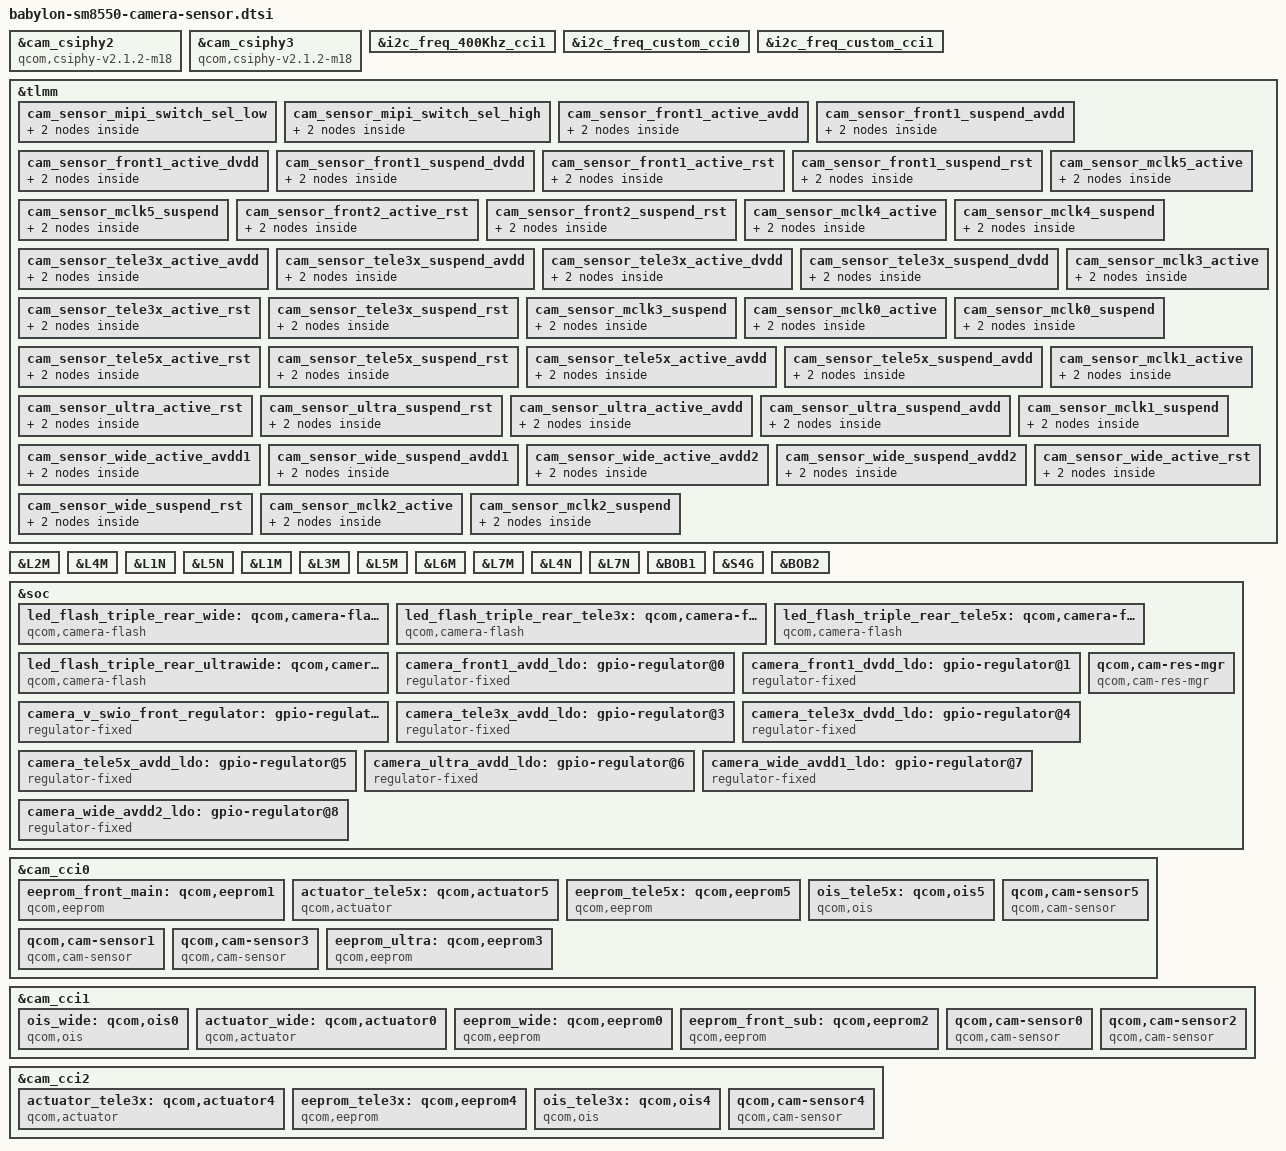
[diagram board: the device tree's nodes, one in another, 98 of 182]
#include <dt-bindings/msm-camera.h>
#include <dt-bindings/gpio/gpio.h>

//wide imx800
&cam_csiphy2 {
	compatible = "qcom,csiphy-v2.1.2-m18", "qcom,csiphy";
};

//tele 5x s5k3k1
&cam_csiphy3 {
	compatible = "qcom,csiphy-v2.1.2-m18", "qcom,csiphy";
};


&i2c_freq_400Khz_cci1 {
	hw-thigh = <38>;
	hw-tlow = <56>;
	hw-tsu-sto = <40>;
	hw-tsu-sta = <40>;
	hw-thd-dat = <22>;
	hw-thd-sta = <35>;
	hw-tbuf = <62>;
	hw-scl-stretch-en = <1>;
	hw-trdhld = <6>;
	hw-tsp = <3>;
	cci-clk-src = <37500000>;
	status = "ok";
};

&i2c_freq_custom_cci0 {
	hw-thigh = <16>;
	hw-tlow = <22>;
	hw-tsu-sto = <17>;
	hw-tsu-sta = <18>;
	hw-thd-dat = <16>;
	hw-thd-sta = <15>;
	hw-tbuf = <24>;
	hw-scl-stretch-en = <1>;
	hw-trdhld = <3>;
	hw-tsp = <3>;
	cci-clk-src = <37500000>;
	status = "ok";
};

&i2c_freq_custom_cci1 {
	hw-thigh = <16>;
	hw-tlow = <22>;
	hw-tsu-sto = <17>;
	hw-tsu-sta = <18>;
	hw-thd-dat = <16>;
	hw-thd-sta = <15>;
	hw-tbuf = <24>;
	hw-scl-stretch-en = <1>;
	hw-trdhld = <3>;
	hw-tsp = <3>;
	cci-clk-src = <37500000>;
	status = "ok";
};

&tlmm {
	cam_sensor_mipi_switch_sel_low: cam_sensor_mipi_switch_sel_low {
		/* MIPI SEL LOW: FRONT(AON) SUB ACTIVE */
		mux {
			pins = "gpio91";
			function = "gpio";
		};

		config {
			pins = "gpio91";
			bias-disable; /* No PULL */
			drive-strength = <2>; /* 2 MA */
		};
	};

	cam_sensor_mipi_switch_sel_high: cam_sensor_mipi_switch_sel_high {
		/* MIPI SEL HIGH: FRONT MAIN ACTIVE */
		mux {
			pins = "gpio91";
			function = "gpio";
		};

		config {
			pins = "gpio91";
			bias-pull-down; /* PULL DOWN */
			drive-strength = <2>; /* 2 MA */
			output-low;
		};
	};
	/* Front1 */
	cam_sensor_front1_active_avdd: cam_sensor_front1_active_avdd {
		mux {
			pins = "gpio180";
			function = "gpio";
		};

		config {
			pins = "gpio180";
			bias-disable; /* No PULL */
			drive-strength = <2>; /* 2 MA */
		};
	};

	cam_sensor_front1_suspend_avdd: cam_sensor_front1_suspend_avdd {
		mux {
			pins = "gpio180";
			function = "gpio";
		};

		config {
			pins = "gpio180";
			bias-pull-down; /* PULL DOWN */
			drive-strength = <2>; /* 2 MA */
			output-low;
		};
	};

	cam_sensor_front1_active_dvdd: cam_sensor_front1_active_dvdd {
		mux {
			pins = "gpio97";
			function = "gpio";
		};

		config {
			pins = "gpio97";
			bias-disable; /* No PULL */
			drive-strength = <2>; /* 2 MA */
		};
	};

	cam_sensor_front1_suspend_dvdd: cam_sensor_front1_suspend_dvdd {
		mux {
			pins = "gpio97";
			function = "gpio";
		};

		config {
			pins = "gpio97";
			bias-pull-down; /* PULL DOWN */
			drive-strength = <2>; /* 2 MA */
			output-low;
		};
	};

	cam_sensor_front1_active_rst: cam_sensor_front1_active_rst {
		mux {
			pins = "gpio42";
			function = "gpio";
		};

		config {
			pins = "gpio42";
			bias-disable; /* No PULL */
			drive-strength = <2>; /* 2 MA */
			qcom,apps;
		};
	};

	cam_sensor_front1_suspend_rst: cam_sensor_front1_suspend_rst {
		mux {
			pins = "gpio42";
			function = "gpio";
		};

		config {
			pins = "gpio42";
			bias-pull-down; /* PULL DOWN */
			drive-strength = <2>; /* 2 MA */
			output-low;
			qcom,remote;
		};
	};

	cam_sensor_mclk5_active: cam_sensor_mclk5_active {
		/* MCLK5 */
		mux {
			pins = "gpio105";
			function = "cam_mclk";
		};

		config {
			pins = "gpio105";
			bias-disable; /* No PULL */
			drive-strength = <4>; /* 4 MA */
		};
	};

	cam_sensor_mclk5_suspend: cam_sensor_mclk5_suspend {
		/* MCLK5 */
		mux {
			pins = "gpio105";
			function = "cam_mclk";
		};

		config {
			pins = "gpio105";
			bias-pull-down; /* PULL DOWN */
			drive-strength = <4>; /* 4 MA */
		};
	};
	/* Front2 */
	cam_sensor_front2_active_rst: cam_sensor_front2_active_rst {
		mux {
			pins = "gpio120";
			function = "gpio";
		};

		config {
			pins = "gpio120";
			bias-disable; /* No PULL */
			drive-strength = <2>; /* 2 MA */
			qcom,apps;
		};
	};

	cam_sensor_front2_suspend_rst: cam_sensor_front2_suspend_rst {
		mux {
			pins = "gpio120";
			function = "gpio";
		};

		config {
			pins = "gpio120";
			bias-pull-down; /* PULL DOWN */
			drive-strength = <2>; /* 2 MA */
			output-low;
			qcom,remote;
		};
	};

	cam_sensor_mclk4_active: cam_sensor_mclk4_active {
		/* MCLK4 */
		mux {
			pins = "gpio104";
			function = "cam_aon_mclk4";
		};

		config {
			pins = "gpio104";
			bias-disable; /* No PULL */
			drive-strength = <4>; /* 4 MA */
		};
	};

	cam_sensor_mclk4_suspend: cam_sensor_mclk4_suspend {
		/* MCLK4 */
		mux {
			pins = "gpio104";
			function = "cam_aon_mclk4";
		};

		config {
			pins = "gpio104";
			bias-pull-down; /* PULL DOWN */
			drive-strength = <4>; /* 4 MA */
		};
	};

	/* tele3x */
	cam_sensor_tele3x_active_avdd: cam_sensor_tele3x_active_avdd {
		mux {
			pins = "gpio68";
			function = "gpio";
		};

		config {
			pins = "gpio68";
			bias-disable; /* No PULL */
			drive-strength = <2>; /* 2 MA */
		};
	};

	cam_sensor_tele3x_suspend_avdd: cam_sensor_tele3x_suspend_avdd {
		mux {
			pins = "gpio68";
			function = "gpio";
		};

		config {
			pins = "gpio68";
			bias-pull-down; /* PULL DOWN */
			drive-strength = <2>; /* 2 MA */
			output-low;
		};
	};

	cam_sensor_tele3x_active_dvdd: cam_sensor_tele3x_active_dvdd {
		mux {
			pins = "gpio128";
			function = "gpio";
		};

		config {
			pins = "gpio128";
			bias-disable; /* No PULL */
			drive-strength = <2>; /* 2 MA */
		};
	};

	cam_sensor_tele3x_suspend_dvdd: cam_sensor_tele3x_suspend_dvdd {
		mux {
			pins = "gpio128";
			function = "gpio";
		};

		config {
			pins = "gpio128";
			bias-pull-down; /* PULL DOWN */
			drive-strength = <2>; /* 2 MA */
			output-low;
		};
	};

	cam_sensor_tele3x_active_rst: cam_sensor_tele3x_active_rst {
		mux {
			pins = "gpio119";
			function = "gpio";
		};

		config {
			pins = "gpio119";
			bias-disable; /* No PULL */
			drive-strength = <2>; /* 2 MA */
		};
	};

	cam_sensor_tele3x_suspend_rst: cam_sensor_tele3x_suspend_rst {
		mux {
			pins = "gpio119";
			function = "gpio";
		};

		config {
			pins = "gpio119";
			bias-pull-down; /* PULL DOWN */
			drive-strength = <2>; /* 2 MA */
			output-low;
		};
	};

	cam_sensor_mclk3_active: cam_sensor_mclk3_active {
		/* MCLK3 */
		mux {
			pins = "gpio103";
			function = "cam_mclk";
		};

		config {
			pins = "gpio103";
			bias-disable; /* No PULL */
			drive-strength = <4>; /* 4 MA */
		};
	};

	cam_sensor_mclk3_suspend: cam_sensor_mclk3_suspend {
		/* MCLK3 */
		mux {
			pins = "gpio103";
			function = "cam_mclk";
		};

		config {
			pins = "gpio103";
			bias-pull-down; /* PULL DOWN */
			drive-strength = <4>; /* 4 MA */
		};
	};

	/*tele 5x*/
	cam_sensor_mclk0_active: cam_sensor_mclk0_active {
		/* MCLK0 */
		mux {
			pins = "gpio100";
			function = "cam_mclk";
		};

		config {
			pins = "gpio100";
			bias-disable; /* No PULL */
			drive-strength = <4>; /* 4 MA */
		};
	};

	cam_sensor_mclk0_suspend: cam_sensor_mclk0_suspend {
		/* MCLK0 */
		mux {
			pins = "gpio100";
			function = "cam_mclk";
		};

		config {
			pins = "gpio100";
			bias-pull-down; /* PULL DOWN */
			drive-strength = <4>; /* 4 MA */
		};
	};

	cam_sensor_tele5x_active_rst: cam_sensor_tele5x_active_rst {
		mux {
			pins = "gpio48";
			function = "gpio";
		};

		config {
			pins = "gpio48";
			bias-disable; /* No PULL */
			drive-strength = <2>; /* 2 MA */
			qcom,apps;
		};
	};

	cam_sensor_tele5x_suspend_rst: cam_sensor_tele5x_suspend_rst {
		mux {
			pins = "gpio48";
			function = "gpio";
		};

		config {
			pins = "gpio48";
			bias-pull-down; /* PULL DOWN */
			drive-strength = <2>; /* 2 MA */
			output-low;
			qcom,remote;
		};

	};

	cam_sensor_tele5x_active_avdd: cam_sensor_tele5x_active_avdd {
		mux {
			pins = "gpio49";
			function = "gpio";
		};

		config {
			pins = "gpio49";
			bias-disable; /* No PULL */
			drive-strength = <2>; /* 2 MA */
		};
	};

	cam_sensor_tele5x_suspend_avdd: cam_sensor_tele5x_suspend_avdd {
		mux {
			pins = "gpio49";
			function = "gpio";
		};

		config {
			pins = "gpio49";
			bias-pull-down; /* PULL DOWN */
			drive-strength = <2>; /* 2 MA */
			output-low;
		};
	};

	/*ultra*/
	cam_sensor_ultra_active_rst: cam_sensor_ultra_active_rst {
		mux {
			pins = "gpio117";
			function = "gpio";
		};

		config {
			pins = "gpio117";
			bias-disable; /* No PULL */
			drive-strength = <2>; /* 2 MA */
		};
	};

	cam_sensor_ultra_suspend_rst: cam_sensor_ultra_suspend_rst {
		mux {
			pins = "gpio117";
			function = "gpio";
		};

		config {
			pins = "gpio117";
			bias-pull-down; /* PULL DOWN */
			drive-strength = <2>; /* 2 MA */
			output-low;
		};
	};

	cam_sensor_ultra_active_avdd: cam_sensor_ultra_active_avdd {
		mux {
			pins = "gpio66";
			function = "gpio";
		};

		config {
			pins = "gpio66";
			bias-disable; /* No PULL */
			drive-strength = <2>; /* 2 MA */
		};
	};

	cam_sensor_ultra_suspend_avdd: cam_sensor_ultra_suspend_avdd {
		mux {
			pins = "gpio66";
			function = "gpio";
		};

		config {
			pins = "gpio66";
			bias-pull-down; /* PULL DOWN */
			drive-strength = <2>; /* 2 MA */
			output-low;
		};
	};

	cam_sensor_mclk1_active: cam_sensor_mclk1_active {
		/* MCLK1 */
		mux {
			pins = "gpio101";
			function = "cam_mclk";
		};

		config {
			pins = "gpio101";
			bias-disable; /* No PULL */
			drive-strength = <6>; /* 6 MA */
		};
	};

	cam_sensor_mclk1_suspend: cam_sensor_mclk1_suspend {
		/* MCLK1 */
		mux {
			pins = "gpio101";
			function = "cam_mclk";
		};

		config {
			pins = "gpio101";
			bias-pull-down; /* PULL DOWN */
			drive-strength = <6>; /* 6 MA */
		};
	};

	/*wide*/
	cam_sensor_wide_active_avdd1: cam_sensor_wide_active_avdd1 {
		mux {
			pins = "gpio88";
			function = "gpio";
		};

		config {
			pins = "gpio88";
			bias-disable; /* No PULL */
			drive-strength = <2>; /* 2 MA */
		};
	};

	cam_sensor_wide_suspend_avdd1: cam_sensor_wide_suspend_avdd1 {
		mux {
			pins = "gpio88";
			function = "gpio";
		};

		config {
			pins = "gpio88";
			bias-pull-down; /* PULL DOWN */
			drive-strength = <2>; /* 2 MA */
			output-low;
		};
	};

	cam_sensor_wide_active_avdd2: cam_sensor_wide_active_avdd2 {
		mux {
			pins = "gpio181";
			function = "gpio";
		};

		config {
			pins = "gpio181";
			bias-disable; /* No PULL */
			drive-strength = <2>; /* 2 MA */
		};
	};

	cam_sensor_wide_suspend_avdd2: cam_sensor_wide_suspend_avdd2 {
		mux {
			pins = "gpio181";
			function = "gpio";
		};

		config {
			pins = "gpio181";
			bias-pull-down; /* PULL DOWN */
			drive-strength = <2>; /* 2 MA */
			output-low;
		};
	};
	cam_sensor_wide_active_rst: cam_sensor_wide_active_rst {
		mux {
			pins = "gpio118";
			function = "gpio";
		};

		config {
			pins = "gpio118";
			bias-disable; /* No PULL */
			drive-strength = <2>; /* 2 MA */
		};
	};

	cam_sensor_wide_suspend_rst: cam_sensor_wide_suspend_rst {
		mux {
			pins = "gpio118";
			function = "gpio";
		};

		config {
			pins = "gpio118";
			bias-pull-down; /* PULL DOWN */
			drive-strength = <2>; /* 2 MA */
			output-low;
		};
	};
	cam_sensor_mclk2_active: cam_sensor_mclk2_active {
		/* MCLK2 */
		mux {
			pins = "gpio102";
			function = "cam_mclk";
		};

		config {
			pins = "gpio102";
			bias-disable; /* No PULL */
			drive-strength = <4>; /* 4 MA */
		};
	};

	cam_sensor_mclk2_suspend: cam_sensor_mclk2_suspend {
		/* MCLK2 */
		mux {
			pins = "gpio102";
			function = "cam_mclk";
		};

		config {
			pins = "gpio102";
			bias-pull-down; /* PULL DOWN */
			drive-strength = <4>; /* 4 MA */
		};
	};
};

&L2M {
	regulator-min-microvolt = <1150000>;
	regulator-max-microvolt = <1150000>;
	qcom,init-voltage = <1150000>;
};

&L4M {
	regulator-min-microvolt = <3104000>;
	regulator-max-microvolt = <3104000>;
	qcom,init-voltage = <3104000>;
};

&L1N {
	regulator-min-microvolt = <1200000>;
	regulator-max-microvolt = <1200000>;
	qcom,init-voltage = <1200000>;
};

&L5N {
	regulator-min-microvolt = <1800000>;
	regulator-max-microvolt = <1800000>;
	qcom,init-voltage = <1800000>;
};

&L1M {
	regulator-min-microvolt = <1200000>;
	regulator-max-microvolt = <1200000>;
	qcom,init-voltage = <1200000>;
};

&L3M {
	regulator-min-microvolt = <2800000>;
	regulator-max-microvolt = <2800000>;
	qcom,init-voltage = <2800000>;
};

&L5M {
	regulator-min-microvolt = <3104000>;
	regulator-max-microvolt = <3104000>;
	qcom,init-voltage = <3104000>;
};

&L6M {
	regulator-min-microvolt = <3104000>;
	regulator-max-microvolt = <3104000>;
	qcom,init-voltage = <3104000>;
};

&L7M {
	regulator-min-microvolt = <3104000>;
	regulator-max-microvolt = <3104000>;
	qcom,init-voltage = <3104000>;
};

&L4N {
	regulator-min-microvolt = <2800000>;
	regulator-max-microvolt = <2800000>;
	qcom,init-voltage = <2800000>;
};

&L7N {
	regulator-min-microvolt = <2800000>;
	regulator-max-microvolt = <2800000>;
	qcom,init-voltage = <2800000>;
};

&BOB1 {
	regulator-min-microvolt = <3008000>;
	regulator-max-microvolt = <3960000>;
};

&S4G {
	regulator-min-microvolt = <1256000>;
	regulator-max-microvolt = <1408000>;
	qcom,init-voltage = <1312000>;
};

&BOB2 {
	regulator-min-microvolt = <2704000>;
	regulator-max-microvolt = <3296000>;
};

&soc {
	led_flash_triple_rear_wide: qcom,camera-flash1 {
		cell-index = <1>;
		compatible = "qcom,camera-flash";
		flash-source = <&pm8550_flash0 &pm8550_flash3>;
		torch-source = <&pm8550_torch0 &pm8550_torch3>;
		switch-source = <&pm8550_switch0>;
		status = "ok";
	};

	led_flash_triple_rear_tele3x: qcom,camera-flash2 {
		cell-index = <2>;
		compatible = "qcom,camera-flash";
		flash-source = <&pm8550_flash0 &pm8550_flash3>;
		torch-source = <&pm8550_torch0 &pm8550_torch3>;
		switch-source = <&pm8550_switch0>;
		status = "ok";
	};

	led_flash_triple_rear_tele5x: qcom,camera-flash3 {
		cell-index = <3>;
		compatible = "qcom,camera-flash";
		flash-source = <&pm8550_flash0 &pm8550_flash3>;
		torch-source = <&pm8550_torch0 &pm8550_torch3>;
		switch-source = <&pm8550_switch0>;
		status = "ok";
	};

	led_flash_triple_rear_ultrawide: qcom,camera-flash4 {
		cell-index = <4>;
		compatible = "qcom,camera-flash";
		flash-source = <&pm8550_flash0 &pm8550_flash3>;
		torch-source = <&pm8550_torch0 &pm8550_torch3>;
		switch-source = <&pm8550_switch0>;
		status = "ok";
	};

	camera_front1_avdd_ldo: gpio-regulator@0 {
		compatible = "regulator-fixed";
		reg = <0x00 0x00>;
		regulator-name = "camera_front1_avdd_ldo";
		regulator-min-microvolt = <2800000>;
		regulator-max-microvolt = <2800000>;
		regulator-enable-ramp-delay = <100>;
		enable-active-high;
		gpio = <&tlmm 180 0>;
		pinctrl-names = "front1_avdd_active", "front1_avdd_suspend";
		pinctrl-0 = <&cam_sensor_front1_active_avdd
					&cam_sensor_front1_suspend_avdd>;
	};

	camera_front1_dvdd_ldo: gpio-regulator@1 {
		compatible = "regulator-fixed";
		reg = <0x01 0x00>;
		regulator-name = "camera_front1_dvdd_ldo";
		regulator-min-microvolt = <1200000>;
		regulator-max-microvolt = <1200000>;
		regulator-enable-ramp-delay = <100>;
		enable-active-high;
		gpio = <&tlmm 97 0>;
		pinctrl-names = "front1_dvdd_active", "front1_dvdd_suspend";
		pinctrl-0 = <&cam_sensor_front1_active_dvdd
					&cam_sensor_front1_suspend_dvdd>;
	};

	//front switch
	camera_v_swio_front_regulator: gpio-regulator@2 {
		compatible = "regulator-fixed";
		reg = <0x02 0x00>;
		regulator-name = "camera_v_swio_front_regulator";
		regulator-min-microvolt = <1800000>;
		regulator-max-microvolt = <1800000>;
		regulator-enable-ramp-delay = <100>;
		enable-active-high;
		gpio = <&tlmm 91 0>;
		pinctrl-names = "mipi_switch_sel_low", "mipi_switch_sel_high";
		pinctrl-0 = <&cam_sensor_mipi_switch_sel_low
					&cam_sensor_mipi_switch_sel_high>;
	};

	camera_tele3x_avdd_ldo: gpio-regulator@3 {
		compatible = "regulator-fixed";
		reg = <0x03 0x00>;
		regulator-name = "camera_tele3x_avdd_ldo";
		regulator-min-microvolt = <2800000>;
		regulator-max-microvolt = <2800000>;
		regulator-enable-ramp-delay = <100>;
		enable-active-high;
		gpio = <&tlmm 68 0>;
		pinctrl-names = "tele3x_avdd_active", "tele3x_avdd_suspend";
		pinctrl-0 = <&cam_sensor_tele3x_active_avdd
					&cam_sensor_tele3x_suspend_avdd>;
	};

	camera_tele3x_dvdd_ldo: gpio-regulator@4 {
		compatible = "regulator-fixed";
		reg = <0x04 0x00>;
		regulator-name = "camera_tele3x_dvdd_ldo";
		regulator-min-microvolt = <1056000>;
		regulator-max-microvolt = <1056000>;
		regulator-enable-ramp-delay = <100>;
		enable-active-high;
		gpio = <&tlmm 128 0>;
		pinctrl-names = "tele3x_dvdd_active", "tele3x_dvdd_suspend";
		pinctrl-0 = <&cam_sensor_tele3x_active_dvdd
					&cam_sensor_tele3x_suspend_dvdd>;

	};

	camera_tele5x_avdd_ldo: gpio-regulator@5 {
		compatible = "regulator-fixed";
		reg = <0x05 0x00>;
		regulator-name = "camera_tele5x_avdd_ldo";
		regulator-min-microvolt = <2800000>;
		regulator-max-microvolt = <2800000>;
		regulator-enable-ramp-delay = <100>;
		enable-active-high;
		gpio = <&tlmm 49 0>;
		pinctrl-names = "tele5x_avdd_active", "tele5x_avdd_suspend";
		pinctrl-0 = <&cam_sensor_tele5x_active_avdd
					&cam_sensor_tele5x_suspend_avdd>;
		//vin-supply = <&BOB2>;
	};

	camera_ultra_avdd_ldo: gpio-regulator@6 {
		compatible = "regulator-fixed";
		reg = <0x06 0x00>;
		regulator-name = "camera_ultra_avdd_ldo";
		regulator-min-microvolt = <2800000>;
		regulator-max-microvolt = <2800000>;
		regulator-enable-ramp-delay = <100>;
		enable-active-high;
		gpio = <&tlmm 66 0>;
		pinctrl-names = "tele_avdd_active", "tele_avdd_suspend";
		pinctrl-0 = <&cam_sensor_ultra_active_avdd
					&cam_sensor_ultra_suspend_avdd>;
		//vin-supply = <&BOB2>;
	};

	camera_wide_avdd1_ldo: gpio-regulator@7 {
		compatible = "regulator-fixed";
		reg = <0x07 0x00>;
		regulator-name = "camera_wide_avdd1_ldo";
		regulator-min-microvolt = <2800000>;
		regulator-max-microvolt = <2800000>;
		regulator-enable-ramp-delay = <100>;
		enable-active-high;
		gpio = <&tlmm 88 0>;
		pinctrl-names = "wide_avdd1_active", "wide_avdd1_suspend";
		pinctrl-0 = <&cam_sensor_wide_active_avdd1
					&cam_sensor_wide_suspend_avdd1>;
		//vin-supply = <&BOB2>;
	};

	camera_wide_avdd2_ldo: gpio-regulator@8 {
		compatible = "regulator-fixed";
		reg = <0x08 0x00>;
		regulator-name = "camera_wide_avdd2_ldo";
		regulator-min-microvolt = <1800000>;
		regulator-max-microvolt = <1800000>;
		regulator-enable-ramp-delay = <100>;
		enable-active-high;
		gpio = <&tlmm 181 0>;
		pinctrl-names = "wide_avdd2_active", "wide_avdd2_suspend";
		pinctrl-0 = <&cam_sensor_wide_active_avdd2
					&cam_sensor_wide_suspend_avdd2>;
		//vin-supply = <&BOB2>;
	};

	qcom,cam-res-mgr {
		compatible = "qcom,cam-res-mgr";
		gpios-shared-pinctrl = <404 420 401 349 403 419>;
		shared-pctrl-gpio-names = "cam_tele3x", "cam_tele3x", "cam_tele5x", "cam_tele5x", "cam_wide", "cam_wide";
		pinctrl-names = "cam_tele3x_active", "cam_tele3x_suspend", "cam_tele5x_active", "cam_tele5x_suspend", "cam_wide_active", "cam_wide_suspend";
		pinctrl-0 = <&cam_sensor_mclk3_active
				&cam_sensor_tele3x_active_rst>;
		pinctrl-1 = <&cam_sensor_mclk3_suspend
				&cam_sensor_tele3x_suspend_rst>;
		pinctrl-2 = <&cam_sensor_mclk0_active
				&cam_sensor_tele5x_active_rst>;
		pinctrl-3 = <&cam_sensor_mclk0_suspend
				&cam_sensor_tele5x_suspend_rst>;
		pinctrl-4 = <&cam_sensor_mclk2_active
			&cam_sensor_wide_active_rst>;
		pinctrl-5 = <&cam_sensor_mclk2_suspend
			&cam_sensor_wide_suspend_rst>;
		status = "ok";
	};

};

&cam_cci0 {
	//Front1 main ov20b eeprom
	eeprom_front_main: qcom,eeprom1 {
		cell-index = <1>;
		compatible = "qcom,eeprom";
		cam_vio-supply = <&L5N>;
		cam_vana-supply = <&camera_front1_avdd_ldo>;
		cam_vdig-supply = <&camera_front1_dvdd_ldo>;
		cam_bob1-supply = <&BOB1>;
		cam_v_custom1-supply = <&S4G>;
		cam_v_custom2-supply = <&camera_v_swio_front_regulator>;
		cam_clk-supply = <&cam_cc_titan_top_gdsc>;
		regulator-names = "cam_vio", "cam_vana", "cam_vdig", "cam_clk", "cam_bob1","cam_v_custom1","cam_v_custom2";
		rgltr-cntrl-support;
		rgltr-min-voltage = <1800000 2800000 1200000 0 3008000 1312000 1800000>;
		rgltr-max-voltage = <1800000 2800000 1200000 0 3960000 1408000 1800000>;
		rgltr-load-current = <103000 20000 454000 0 2000000 454000 103000>;
		//use-shared-clk;
		gpio-no-mux = <0>;
		pinctrl-names = "cam_default", "cam_suspend";
		pinctrl-0 = <&cam_sensor_mclk5_active
				&cam_sensor_front1_active_rst>;
		pinctrl-1 = <&cam_sensor_mclk5_suspend
				&cam_sensor_front1_suspend_rst>;
		gpios = <&tlmm 105 0>,//MCLK5
			<&tlmm 42 0>;//RST
		gpio-reset = <1>;
		gpio-req-tbl-num = <0 1>;
		gpio-req-tbl-flags = <1 0>;
		gpio-req-tbl-label = "CAMIF_MCLK5",
					"CAM_RESET5";
		cci-device = <0>;
		cci-master = <1>;
		clocks = <&camcc CAM_CC_MCLK5_CLK>;
		clock-names = "cam_clk";
		clock-cntl-level = "nominal";
		clock-rates = <19200000>;
		status = "ok";
	};

	/* tele5x actuator */
	actuator_tele5x: qcom,actuator5 {
		cell-index = <5>;
		compatible = "qcom,actuator";
		cci-master = <CCI_MASTER_0>;
		cam_vio-supply = <&L5N>;  					 //DOVDD PM8010 LDO5 1.8V
		cam_vdig-supply = <&L2N>;
		cam_clk-supply = <&cam_cc_titan_top_gdsc>;   // mclk gpio119
		cam_vana-supply = <&camera_tele5x_avdd_ldo>; //AVDD gpio97 2.8V
		cam_bob1-supply = <&BOB1>;
		cam_bob2-supply = <&BOB2>;
		cam_vaf-supply = <&L7N>;
		cam_v_custom1-supply = <&L4N>;
		regulator-names = "cam_vio","cam_vdig", "cam_clk",
			"cam_vana","cam_bob1", "cam_bob2", "cam_vaf", "cam_v_custom1";
		rgltr-cntrl-support;
		rgltr-min-voltage = <1800000 1104000 0 2800000 3604000 2704000 2800000 2800000>;
		rgltr-max-voltage = <1800000 1104000 0 2800000 3960000 3296000 2800000 2800000>;
		rgltr-load-current = <20000  166000  0 60000   103000  103000 330000 30000>;
	};

	/* tele5x eeprom */
		eeprom_tele5x: qcom,eeprom5 {
		cell-index = <5>;
		compatible = "qcom,eeprom";
		cam_vio-supply = <&L5N>;  					 //DOVDD PM8010 LDO5 1.8V
		cam_vdig-supply = <&L2N>;
		cam_clk-supply = <&cam_cc_titan_top_gdsc>;   // mclk gpio119
		cam_vana-supply = <&camera_tele5x_avdd_ldo>; //AVDD gpio97 2.8V
		cam_bob1-supply = <&BOB1>;
		cam_bob2-supply = <&BOB2>;
		cam_vaf-supply = <&L7N>;
		cam_v_custom1-supply = <&L4N>;
		regulator-names = "cam_vio","cam_vdig", "cam_clk",
			"cam_vana","cam_bob1", "cam_bob2", "cam_vaf", "cam_v_custom1";
		rgltr-cntrl-support;
		rgltr-min-voltage = <1800000 1104000 0 2800000 3604000 2704000 2800000 2800000>;
		rgltr-max-voltage = <1800000 1104000 0 2800000 3960000 3296000 2800000 2800000>;
		rgltr-load-current = <20000  166000  0 60000   103000  103000 330000 30000>;
		gpio-no-mux = <0>;
		use-shared-clk;
		gpios = <&tlmm 100 0>,
			<&tlmm 48 0>;
		gpio-reset = <1>;
		gpio-req-tbl-num = <0 1>;
		gpio-req-tbl-flags = <1 0>;
		gpio-req-tbl-label = "CAMIF_MCLK0",
					"CAM_RESET0";
		cci-master = <CCI_MASTER_0>;
		clocks = <&camcc CAM_CC_MCLK0_CLK>;
		clock-names = "cam_clk";
		clock-cntl-level = "nominal";
		clock-rates = <19200000>;
		status = "ok";
	};

	/* tele5x ois */
	ois_tele5x: qcom,ois5 {
		cell-index = <5>;
		compatible = "qcom,ois";
		cam_vio-supply = <&L5N>;  					 //DOVDD PM8010 LDO5 1.8V
		cam_vdig-supply = <&L2N>;
		cam_clk-supply = <&cam_cc_titan_top_gdsc>;   // mclk gpio119
		cam_vana-supply = <&camera_tele5x_avdd_ldo>; //AVDD gpio97 2.8V
		cam_bob1-supply = <&BOB1>;
		cam_bob2-supply = <&BOB2>;
		cam_vaf-supply = <&L7N>;
		cam_v_custom1-supply = <&L4N>;
		regulator-names = "cam_vio","cam_vdig", "cam_clk",
			"cam_vana","cam_bob1", "cam_bob2", "cam_vaf", "cam_v_custom1";
		rgltr-cntrl-support;
		rgltr-min-voltage = <1800000 1104000 0 2800000 3604000 2704000 2800000 2800000>;
		rgltr-max-voltage = <1800000 1104000 0 2800000 3960000 3296000 2800000 2800000>;
		rgltr-load-current = <20000  166000  0 60000   103000  103000 330000 30000>;
		gpio-no-mux = <0>;
		use-shared-clk;
		gpios = <&tlmm 100 0>,
			<&tlmm 48 0>;
		gpio-reset = <1>;
		gpio-req-tbl-num = <0 1>;
		gpio-req-tbl-flags = <1 0>;
		gpio-req-tbl-label = "CAMIF_MCLK0",
					"CAM_RESET0";
		cci-master = <CCI_MASTER_0>;
		clocks = <&camcc CAM_CC_MCLK0_CLK>;
		clock-names = "cam_clk";
		clock-cntl-level = "nominal";
		clock-rates = <19200000>;
		status = "ok";
	};

	/* tele5x s5k3k1*/
	qcom,cam-sensor5 {
		cell-index = <5>;
		compatible = "qcom,cam-sensor";
		csiphy-sd-index = <3>;
		actuator-src = <&actuator_tele5x>;
		eeprom-src = <&eeprom_tele5x>;
		led-flash-src = <&led_flash_triple_rear_tele5x>;
		ois-src  = <&ois_tele5x>;
		sensor-position-roll = <90>;
		sensor-position-pitch = <0>;
		sensor-position-yaw = <180>;
		cam_vio-supply = <&L5N>;  					 //DOVDD PM8010 LDO5 1.8V
		cam_vdig-supply = <&L2N>;
		cam_clk-supply = <&cam_cc_titan_top_gdsc>;   // mclk gpio119
		cam_vana-supply = <&camera_tele5x_avdd_ldo>; //AVDD gpio97 2.8V
		cam_bob1-supply = <&BOB1>;
		cam_bob2-supply = <&BOB2>;
		cam_vaf-supply = <&L7N>;
		cam_v_custom1-supply = <&L4N>;
		regulator-names = "cam_vio","cam_vdig", "cam_clk",
			"cam_vana","cam_bob1", "cam_bob2", "cam_vaf", "cam_v_custom1";
		rgltr-cntrl-support;
		rgltr-min-voltage = <1800000 1104000 0 2800000 3604000 2704000 2800000 2800000>;
		rgltr-max-voltage = <1800000 1104000 0 2800000 3960000 3296000 2800000 2800000>;
		rgltr-load-current = <20000  166000  0 60000   103000  103000 330000 30000>;
		gpio-no-mux = <0>;
		use-shared-clk;
		gpios = <&tlmm 100 0>,
			<&tlmm 48 0>;
		gpio-reset = <1>;
		gpio-req-tbl-num = <0 1>;
		gpio-req-tbl-flags = <1 0>;
		gpio-req-tbl-label = "CAMIF_MCLK0",
					"CAM_RESET0";
		cci-master = <CCI_MASTER_0>;
		clocks = <&camcc CAM_CC_MCLK0_CLK>;
		clock-names = "cam_clk";
		clock-cntl-level = "nominal";
		clock-rates = <19200000>;
		status = "ok";
	};

	//Front1 main ov20b
	qcom,cam-sensor1 {
		cell-index = <1>;
		compatible = "qcom,cam-sensor";
		csiphy-sd-index = <4>;
		eeprom-src = <&eeprom_front_main>;
		sensor-position-roll = <270>;
		sensor-position-pitch = <0>;
		sensor-position-yaw = <0>;
		cam_vio-supply = <&L5N>;
		cam_vana-supply = <&camera_front1_avdd_ldo>;
		cam_vdig-supply = <&camera_front1_dvdd_ldo>;
		cam_bob1-supply = <&BOB1>;
		cam_v_custom1-supply = <&S4G>;
		cam_v_custom2-supply = <&camera_v_swio_front_regulator>;
		cam_clk-supply = <&cam_cc_titan_top_gdsc>;
		regulator-names = "cam_vio", "cam_vana", "cam_vdig", "cam_clk", "cam_bob1","cam_v_custom1","cam_v_custom2";
		rgltr-cntrl-support;
		rgltr-min-voltage = <1800000 2800000 1200000 0 3008000 1312000 1800000>;
		rgltr-max-voltage = <1800000 2800000 1200000 0 3960000 1408000 1800000>;
		rgltr-load-current = <103000 20000 454000 0 2000000 454000 103000>;
		//use-shared-clk;
		gpio-no-mux = <0>;
		pinctrl-names = "cam_default", "cam_suspend";
		pinctrl-0 = <&cam_sensor_mclk5_active
				&cam_sensor_front1_active_rst>;
		pinctrl-1 = <&cam_sensor_mclk5_suspend
				&cam_sensor_front1_suspend_rst>;
		gpios = <&tlmm 105 0>,//MCLK5
			<&tlmm 42 0>;//RST
		gpio-reset = <1>;
		gpio-req-tbl-num = <0 1>;
		gpio-req-tbl-flags = <1 0>;
		gpio-req-tbl-label = "CAMIF_MCLK5",
					"CAM_RESET5";
		cci-device = <0>;
		cci-master = <1>;
		clocks = <&camcc CAM_CC_MCLK5_CLK>;
		clock-names = "cam_clk";
		clock-cntl-level = "nominal";
		clock-rates = <19200000>;
		status = "ok";
	};

	//Ultra ov13b10
	qcom,cam-sensor3 {
		cell-index = <3>;
		compatible = "qcom,cam-sensor";
		csiphy-sd-index = <1>;
		eeprom-src = <&eeprom_ultra>;
		led-flash-src = <&led_flash_triple_rear_ultrawide>;
		sensor-position-roll = <90>;
		sensor-position-pitch = <0>;
		sensor-position-yaw = <180>;
		cam_vio-supply = <&L5N>;
		cam_vdig-supply = <&L1N>;
		cam_clk-supply = <&cam_cc_titan_top_gdsc>;
		cam_vana-supply = <&camera_ultra_avdd_ldo>;
		cam_bob1-supply = <&BOB1>;
		cam_bob2-supply = <&BOB2>;
		regulator-names = "cam_vio", "cam_vdig",
			"cam_clk", "cam_vana", "cam_bob1","cam_bob2";
		rgltr-cntrl-support;
		rgltr-min-voltage = <1800000 1200000 0 2800000 3008000 2704000>;
		rgltr-max-voltage = <1800000 1200000 0 2800000 3960000 3296000>;
		rgltr-load-current = <155000 680000 0 50000 103000 103000>;
		//use-shared-clk;
		gpio-no-mux = <0>;
		pinctrl-names = "cam_default", "cam_suspend";
		pinctrl-0 = <&cam_sensor_mclk1_active
			&cam_sensor_ultra_active_rst>;
		pinctrl-1 = <&cam_sensor_mclk1_suspend
			&cam_sensor_ultra_suspend_rst>;
		gpios = <&tlmm 101 0>,
			<&tlmm 117 0>;
		gpio-reset = <1>;
		gpio-req-tbl-num = <0 1>;
		gpio-req-tbl-flags = <1 0>;
		gpio-req-tbl-label = "CAMIF_MCLK1",
					"CAM_RESET1";
		cci-master = <CCI_MASTER_1>;
		clocks = <&camcc CAM_CC_MCLK1_CLK>;
		clock-names = "cam_clk";
		clock-cntl-level = "nominal";
		clock-rates = <19200000>;
		status = "ok";
	};

	eeprom_ultra: qcom,eeprom3 {
		cell-index = <3>;
		compatible = "qcom,eeprom";
		cam_vio-supply = <&L5N>;
		cam_vdig-supply = <&L1N>;
		cam_clk-supply = <&cam_cc_titan_top_gdsc>;
		cam_vana-supply = <&camera_ultra_avdd_ldo>;
		cam_bob1-supply = <&BOB1>;
		cam_bob2-supply = <&BOB2>;
		regulator-names = "cam_vio", "cam_vdig",
			"cam_clk", "cam_vana", "cam_bob1","cam_bob2";
		rgltr-cntrl-support;
		rgltr-min-voltage = <1800000 1200000 0 2800000 3008000 2704000>;
		rgltr-max-voltage = <1800000 1200000 0 2800000 3960000 3296000>;
		rgltr-load-current = <155000 680000 0 50000 103000 103000>;
		pinctrl-names = "cam_default", "cam_suspend";
		pinctrl-0 = <&cam_sensor_mclk1_active
			&cam_sensor_ultra_active_rst>;
		pinctrl-1 = <&cam_sensor_mclk1_suspend
			&cam_sensor_ultra_suspend_rst>;
		gpios = <&tlmm 101 0>,
			<&tlmm 117 0>;
		gpio-reset = <1>;
		gpio-req-tbl-num = <0 1>;
		gpio-req-tbl-flags = <1 0>;
		gpio-req-tbl-label = "CAMIF_MCLK1",
					"CAM_RESET1";
		cci-master = <CCI_MASTER_1>;
		clocks = <&camcc CAM_CC_MCLK1_CLK>;
		clock-names = "cam_clk";
		clock-cntl-level = "nominal";
		clock-rates = <19200000>;
		status = "ok";
	};
};

&cam_cci1 {
	ois_wide: qcom,ois0 {
		cell-index = <0>;
		compatible = "qcom,ois";
		cam_vio-supply = <&L5N>;
		cam_vdig-supply = <&L2M>;
		cam_clk-supply = <&cam_cc_titan_top_gdsc>;
		cam_vana-supply = <&camera_wide_avdd1_ldo>;
		cam_v_custom1-supply = <&camera_wide_avdd2_ldo>;
		cam_v_custom2-supply = <&L7M>;                       //ois-vaf
		cam_vaf-supply = <&L4M>;
		cam_bob2-supply = <&BOB2>;
		regulator-names = "cam_vio", "cam_vdig",
			"cam_clk", "cam_vana", "cam_v_custom1",
			"cam_v_custom2", "cam_vaf", "cam_bob2";
		rgltr-cntrl-support;
		rgltr-min-voltage = <1800000 1150000 0 2800000 1800000 3104000 3104000 2704000>;
		rgltr-max-voltage = <1800000 1150000 0 2800000 1800000 3104000 3104000 3296000>;
		rgltr-load-current = <155000 557000 0 93000 62000 200000 120000 103000>;
		use-shared-clk;
		gpio-no-mux = <0>;
		gpios = <&tlmm 102 0>,
			<&tlmm 118 0>;
		gpio-reset = <1>;
		gpio-req-tbl-num = <0 1>;
		gpio-req-tbl-flags = <1 0>;
		gpio-req-tbl-label = "CAMIF_MCLK2",
					"CAM_RESET2";
		cci-master = <CCI_MASTER_0>;
		clocks = <&camcc CAM_CC_MCLK2_CLK>;
		clock-names = "cam_clk";
		clock-cntl-level = "nominal";
		clock-rates = <19200000>;
		status = "ok";
	};
	actuator_wide: qcom,actuator0 {
		cell-index = <0>;
		compatible = "qcom,actuator";
		cci-master = <CCI_MASTER_0>;
		cam_vaf-supply = <&L4M>;
		cam_vio-supply = <&L5N>;
		regulator-names = "cam_vaf", "cam_vio";
		rgltr-cntrl-support;
		rgltr-min-voltage = <3104000 1800000>;
		rgltr-max-voltage = <3104000 1800000>;
		rgltr-load-current = <120000 20000>;
	};
	//Wide eeprom
	eeprom_wide: qcom,eeprom0 {
		cell-index = <0>;
		compatible = "qcom,eeprom";
		cam_vio-supply = <&L5N>;
		cam_vdig-supply = <&L2M>;
		cam_clk-supply = <&cam_cc_titan_top_gdsc>;
		cam_vana-supply = <&camera_wide_avdd1_ldo>;
		cam_v_custom1-supply = <&camera_wide_avdd2_ldo>;
		cam_v_custom2-supply = <&L7M>;                       //ois-vaf
		cam_vaf-supply = <&L4M>;
		cam_bob2-supply = <&BOB2>;
		regulator-names = "cam_vio", "cam_vdig",
			"cam_clk", "cam_vana", "cam_v_custom1",
			"cam_v_custom2", "cam_vaf", "cam_bob2";
		rgltr-cntrl-support;
		rgltr-min-voltage = <1800000 1150000 0 2800000 1800000 3104000 3104000 2704000>;
		rgltr-max-voltage = <1800000 1150000 0 2800000 1800000 3104000 3104000 3296000>;
		rgltr-load-current = <155000 557000 0 93000 62000 200000 120000 103000>;
		use-shared-clk;
		gpio-no-mux = <0>;
		gpios = <&tlmm 102 0>,
			<&tlmm 118 0>;
		gpio-reset = <1>;
		gpio-req-tbl-num = <0 1>;
		gpio-req-tbl-flags = <1 0>;
		gpio-req-tbl-label = "CAMIF_MCLK2",
					"CAM_RESET2";
		cci-master = <CCI_MASTER_0>;
		clocks = <&camcc CAM_CC_MCLK2_CLK>;
		clock-names = "cam_clk";
		clock-cntl-level = "nominal";
		clock-rates = <19200000>;
		status = "ok";
	};

	//Front2 sub ov20b eeprom
	eeprom_front_sub: qcom,eeprom2 {
		cell-index = <2>;
		compatible = "qcom,eeprom";
		cam_vio-supply = <&L5N>;
		cam_vana-supply = <&L3M>;
		cam_vdig-supply = <&L1M>;
		cam_clk-supply = <&cam_cc_titan_top_gdsc>;
		cam_bob1-supply = <&BOB1>;
		cam_v_custom1-supply = <&S4G>;
		cam_v_custom2-supply = <&camera_v_swio_front_regulator>;//mipi switch
		regulator-names = "cam_vio", "cam_vana", "cam_vdig", "cam_clk", "cam_bob1","cam_v_custom1","cam_v_custom2";
		rgltr-cntrl-support;
		rgltr-min-voltage = <1800000 2800000 1200000 0 3008000 1312000 1800000>;
		rgltr-max-voltage = <1800000 2800000 1200000 0 3960000 1408000 1800000>;
		rgltr-load-current = <103000 20000 454000 0 2000000 454000 103000>;
		gpio-no-mux = <0>;
		pinctrl-names = "cam_default", "cam_suspend";
		pinctrl-0 = <&cam_sensor_mclk4_active
				&cam_sensor_front2_active_rst>;
		pinctrl-1 = <&cam_sensor_mclk4_suspend
				&cam_sensor_front2_suspend_rst>;
		gpios = <&tlmm 104 0>,//MCLK5
			<&tlmm 120 0>;//RST
		gpio-reset = <1>;
		gpio-req-tbl-num = <0 1>;
		gpio-req-tbl-flags = <1 0>;
		gpio-req-tbl-label = "CAMIF_MCLK4",
					"CAM_RESET4";
		cci-master = <CCI_MASTER_1>;
		clocks = <&camcc CAM_CC_MCLK4_CLK>;
		clock-names = "cam_clk";
		clock-cntl-level = "nominal";
		clock-rates = <19200000>;
		status = "ok";
	};

	//Wide imx800
	qcom,cam-sensor0 {
		cell-index = <0>;
		compatible = "qcom,cam-sensor";
		csiphy-sd-index = <2>;
		eeprom-src = <&eeprom_wide>;
		actuator-src = <&actuator_wide>;
		ois-src  = <&ois_wide>;
		led-flash-src = <&led_flash_triple_rear_wide>;
		sensor-position-roll = <90>;
		sensor-position-pitch = <0>;
		sensor-position-yaw = <180>;
		cam_vio-supply = <&L5N>;
		cam_vdig-supply = <&L2M>;
		cam_clk-supply = <&cam_cc_titan_top_gdsc>;
		cam_vana-supply = <&camera_wide_avdd1_ldo>;
		cam_v_custom1-supply = <&camera_wide_avdd2_ldo>;
		cam_v_custom2-supply = <&L7M>;                       //ois-vaf
		cam_vaf-supply = <&L4M>;
		cam_bob2-supply = <&BOB2>;
		regulator-names = "cam_vio", "cam_vdig",
			"cam_clk", "cam_vana", "cam_v_custom1",
			"cam_v_custom2", "cam_vaf", "cam_bob2";
		rgltr-cntrl-support;
		rgltr-min-voltage = <1800000 1150000 0 2800000 1800000 3104000 3104000 2704000>;
		rgltr-max-voltage = <1800000 1150000 0 2800000 1800000 3104000 3104000 3296000>;
		rgltr-load-current = <155000 557000 0 93000 62000 200000 120000 103000>;
		use-shared-clk;
		gpio-no-mux = <0>;
		// pinctrl-names = "cam_default", "cam_suspend";
		// pinctrl-0 = <&cam_sensor_mclk2_active
		// 		&cam_sensor_wide_active_rst>;
		// pinctrl-1 = <&cam_sensor_mclk2_suspend
		// 		&cam_sensor_wide_suspend_rst>;
		gpios = <&tlmm 102 0>,
			<&tlmm 118 0>;
		gpio-reset = <1>;
		gpio-req-tbl-num = <0 1>;
		gpio-req-tbl-flags = <1 0>;
		gpio-req-tbl-label = "CAMIF_MCLK2",
					"CAM_RESET2";
		cci-master = <CCI_MASTER_0>;
		clocks = <&camcc CAM_CC_MCLK2_CLK>;
		clock-names = "cam_clk";
		clock-cntl-level = "nominal";
		clock-rates = <19200000>;
		status = "ok";
	};

	//Front2 sub ov20b
	qcom,cam-sensor2 {
		cell-index = <2>;
		compatible = "qcom,cam-sensor";
		csiphy-sd-index = <4>;
		eeprom-src = <&eeprom_front_sub>;
		sensor-position-roll = <270>;
		sensor-position-pitch = <0>;
		sensor-position-yaw = <0>;
		aon-camera-id = <AON_CAM1>;
		cam_vio-supply = <&L5N>;
		cam_vana-supply = <&L3M>;
		cam_vdig-supply = <&L1M>;
		cam_clk-supply = <&cam_cc_titan_top_gdsc>;
		cam_bob1-supply = <&BOB1>;
		cam_v_custom1-supply = <&S4G>;
		cam_v_custom2-supply = <&camera_v_swio_front_regulator>;//mipi switch
		regulator-names = "cam_vio", "cam_vana", "cam_vdig", "cam_clk", "cam_bob1","cam_v_custom1","cam_v_custom2";
		rgltr-cntrl-support;
		rgltr-min-voltage = <1800000 2800000 1200000 0 3008000 1312000 1800000>;
		rgltr-max-voltage = <1800000 2800000 1200000 0 3960000 1408000 1800000>;
		rgltr-load-current = <103000 20000 454000 0 2000000 454000 103000>;
		gpio-no-mux = <0>;
		pinctrl-names = "cam_default", "cam_suspend";
		pinctrl-0 = <&cam_sensor_mclk4_active
				&cam_sensor_front2_active_rst>;
		pinctrl-1 = <&cam_sensor_mclk4_suspend
				&cam_sensor_front2_suspend_rst>;
		gpios = <&tlmm 104 0>,//MCLK5
			<&tlmm 120 0>;//RST
		gpio-reset = <1>;
		gpio-req-tbl-num = <0 1>;
		gpio-req-tbl-flags = <1 0>;
		gpio-req-tbl-label = "CAMIF_MCLK4",
					"CAM_RESET4";
		cci-master = <CCI_MASTER_1>;
		clocks = <&camcc CAM_CC_MCLK4_CLK>;
		clock-names = "cam_clk";
		clock-cntl-level = "nominal";
		clock-rates = <19200000>;
		status = "ok";
	};

};

&cam_cci2 {
	/* tele3x actuator */
	actuator_tele3x: qcom,actuator4 {
		cell-index = <4>;
		compatible = "qcom,actuator";
		cci-master = <CCI_MASTER_0>;
		cam_vaf-supply = <&L6M>;
		cam_vio-supply = <&L5N>;
		cam_bob-supply = <&BOB1>;
		cam_v_custom1-supply = <&L5M>; //OIS PM8010_1 LDO5 3.1V
		regulator-names = "cam_vaf", "cam_vio", "cam_bob", "cam_v_custom1";
		rgltr-cntrl-support;
		rgltr-min-voltage = <3104000 1800000 3604000 3104000>;
		rgltr-max-voltage = <3104000 1800000 3960000 3104000>;
		rgltr-load-current = <120000 20000 103000 103000>;
	};

	/* tele3x eeprom */
		eeprom_tele3x: qcom,eeprom4 {
		cell-index = <4>;
		compatible = "qcom,eeprom";
		cam_vio-supply = <&L5N>;//DOVDD PM8010 LDO5 1.8V
		cam_vdig-supply = <&camera_tele3x_dvdd_ldo>;
		cam_clk-supply = <&cam_cc_titan_top_gdsc>;   // mclk gpio119
		cam_vana-supply = <&camera_tele3x_avdd_ldo>; //AVDD gpio97 2.8V
		cam_vaf-supply = <&L6M>;//AF PM8008 LDO6 3.1V
		cam_bob1-supply = <&BOB1>;
		cam_bob2-supply = <&BOB2>;
		cam_v_custom1-supply = <&L5M>; //OIS PM8010_1 LDO5 3.1V
		regulator-names = "cam_vio","cam_vdig", "cam_clk",
			"cam_vana", "cam_vaf", "cam_bob1", "cam_bob2", "cam_v_custom1";
		rgltr-cntrl-support;
		rgltr-min-voltage = <1800000 1056000 0 2800000 3104000 3604000 2704000 3104000>;
		rgltr-max-voltage = <1800000 1056000 0 2800000 3104000 3960000 3296000 3104000>;
		rgltr-load-current = <20000  166000  0 60000   120000  103000  103000  330000>;
		gpio-no-mux = <0>;
		use-shared-clk;
		gpios = <&tlmm 103 0>,
			<&tlmm 119 0>;
		gpio-reset = <1>;
		gpio-req-tbl-num = <0 1>;
		gpio-req-tbl-flags = <1 0>;
		gpio-req-tbl-label = "CAMIF_MCLK3",
			"CAM_RESET3";
		cci-master = <CCI_MASTER_0>;
		clocks = <&camcc CAM_CC_MCLK3_CLK>;
		clock-names = "cam_clk";
		clock-cntl-level = "nominal";
		clock-rates = <19200000>;
		status = "ok";
	};

	/* tele3x ois */
	ois_tele3x: qcom,ois4 {
		cell-index = <4>;
		compatible = "qcom,ois";
		cam_vio-supply = <&L5N>;  					 //DOVDD PM8010_2 LDO5 1.8V
		cam_vdig-supply = <&camera_tele3x_dvdd_ldo>;
		cam_clk-supply = <&cam_cc_titan_top_gdsc>;   // mclk gpio119
		cam_vana-supply = <&camera_tele3x_avdd_ldo>; //AVDD gpio97 2.8V
		cam_vaf-supply = <&L6M>;					 //AF PM8008 LDO6 3.1V
		cam_bob1-supply = <&BOB1>;
		cam_bob2-supply = <&BOB2>;
		cam_v_custom1-supply = <&L5M>; //OIS PM8010_1 LDO5 3.1V
		regulator-names = "cam_vio", "cam_vdig", "cam_clk",
			"cam_vana", "cam_vaf", "cam_bob1", "cam_bob2", "cam_v_custom1";
		rgltr-cntrl-support;
		rgltr-min-voltage = <1800000 1056000 0 2800000 3104000 3604000 2704000 3104000>;
		rgltr-max-voltage = <1800000 1056000 0 2800000 3104000 3960000 3296000 3104000>;
		rgltr-load-current = <20000  166000  0 60000   120000  103000  103000 330000>;
		gpio-no-mux = <0>;
		use-shared-clk;
		gpios = <&tlmm 103 0>,
			<&tlmm 119 0>;
		gpio-reset = <1>;
		gpio-req-tbl-num = <0 1>;
		gpio-req-tbl-flags = <1 0>;
		gpio-req-tbl-label = "CAMIF_MCLK3",
			"CAM_RESET3";
		cci-master = <CCI_MASTER_0>;
		clocks = <&camcc CAM_CC_MCLK3_CLK>;
		clock-names = "cam_clk";
		clock-cntl-level = "nominal";
		clock-rates = <19200000>;
		status = "ok";
	};

	/* tele3x s5k3k1 */
	qcom,cam-sensor4 {
		cell-index = <4>;
		compatible = "qcom,cam-sensor";
		csiphy-sd-index = <0>;
		actuator-src = <&actuator_tele3x>;
		eeprom-src = <&eeprom_tele3x>;
		led-flash-src = <&led_flash_triple_rear_tele3x>;
		ois-src  = <&ois_tele3x>;
		sensor-position-roll = <90>;
		sensor-position-pitch = <0>;
		sensor-position-yaw = <180>;
		cam_vio-supply = <&L5N>;//DOVDD PM8010_2 LDO5 1.8V
		cam_vdig-supply = <&camera_tele3x_dvdd_ldo>;
		cam_clk-supply = <&cam_cc_titan_top_gdsc>;   // mclk gpio119
		cam_vana-supply = <&camera_tele3x_avdd_ldo>; //AVDD gpio97 2.8V
		cam_vaf-supply = <&L6M>;//AF PM8008 LDO6 3.1V
		cam_bob1-supply = <&BOB1>;
		cam_bob2-supply = <&BOB2>;
		cam_v_custom1-supply = <&L5M>; //OIS PM8010_1 LDO5 3.1V
		regulator-names = "cam_vio","cam_vdig", "cam_clk",
			"cam_vana","cam_vaf","cam_bob1", "cam_bob2", "cam_v_custom1";
		rgltr-cntrl-support;
		rgltr-min-voltage = <1800000 1056000 0 2800000 3104000 3604000 2704000 3104000>;
		rgltr-max-voltage = <1800000 1056000 0 2800000 3104000 3960000 3296000 3104000>;
		rgltr-load-current = <20000  166000  0 60000   120000  103000  103000  330000>;
		gpio-no-mux = <0>;
		use-shared-clk;
		gpios = <&tlmm 103 0>,
			<&tlmm 119 0>;
		gpio-reset = <1>;
		gpio-req-tbl-num = <0 1>;
		gpio-req-tbl-flags = <1 0>;
		gpio-req-tbl-label = "CAMIF_MCLK3",
			"CAM_RESET3";
		cci-master = <CCI_MASTER_0>;
		clocks = <&camcc CAM_CC_MCLK3_CLK>;
		clock-names = "cam_clk";
		clock-cntl-level = "nominal";
		clock-rates = <19200000>;
		status = "ok";
	};
};
